# CH585SFR register map
Vendor: WCH Ltd.; Series: CH58x; File version: 1.1
CPU: RISC-V r0p0, little endian, no MPU, no FPU, 2 interrupt priority bits
Registers are 8-bit, read-write, reset 0x0 unless marked. A register's access mark holds for its fields unless they carry their own. Offsets are from the block's base; [hi:lo] are bit positions; lines under a group give offsets from that group; {n}, {i} and the like mark numbered series.

## SPI1
Base 0x40004400
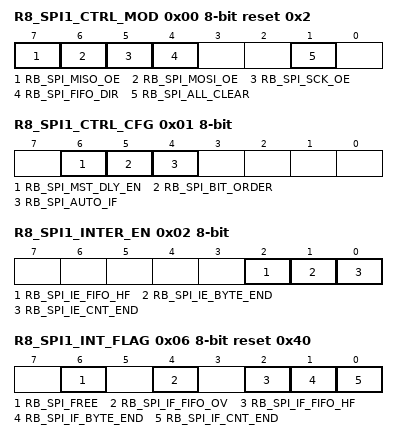
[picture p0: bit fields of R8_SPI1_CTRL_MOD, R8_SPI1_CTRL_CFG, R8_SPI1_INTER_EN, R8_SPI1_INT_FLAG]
0x00 R8_SPI1_CTRL_MOD reset 0x2 — RW, SPI1 mode control
  [7] RB_SPI_MISO_OE — RW, SPI MISO output enable
  [6] RB_SPI_MOSI_OE — RW, SPI MOSI output enable
  [5] RB_SPI_SCK_OE — RW, SPI SCK output enable
  [4] RB_SPI_FIFO_DIR — RW, SPI FIFO direction: 0=out(write @master mode), 1=in(read @master mode)
  [1] RB_SPI_ALL_CLEAR — RW, force clear SPI FIFO and count
0x01 R8_SPI1_CTRL_CFG — RW, SPI1 configuration control
  [6] RB_SPI_MST_DLY_EN — RW, SPI master input delay enable
  [5] RB_SPI_BIT_ORDER — RW, SPI bit data order: 0=MSB first, 1=LSB first
  [4] RB_SPI_AUTO_IF — RW, enable buffer/FIFO accessing to auto clear RB_SPI_IF_BYTE_END interrupt flag
0x02 R8_SPI1_INTER_EN — RW, SPI0 interrupt enable
  [2] RB_SPI_IE_FIFO_HF — RW, enable interrupt for SPI FIFO half
  [1] RB_SPI_IE_BYTE_END — RW, enable interrupt for SPI byte exchanged
  [0] RB_SPI_IE_CNT_END — RW, enable interrupt for SPI total byte count end
0x03 R8_SPI1_CLOCK_DIV reset 0x10 — RW, SPI1 master clock divisor;RW, SPI1 slave preset value
0x04 R8_SPI1_BUFFER reset not defined — RW, SPI1 data buffer
0x05 R8_SPI1_RUN_FLAG ro — RO, SPI1 work flag
  [5] RB_SPI_FIFO_READY — RO, SPI FIFO ready status
0x06 R8_SPI1_INT_FLAG reset 0x40 — RW1, SPI1 interrupt flag
  [6] RB_SPI_FREE — RO, current SPI free status
  [4] RB_SPI_IF_FIFO_OV — RW1, interrupt flag for SPI1 FIFO overflow
  [2] RB_SPI_IF_FIFO_HF — RW1, interrupt flag for SPI FIFO half
  [1] RB_SPI_IF_BYTE_END — RW1, interrupt flag for SPI byte exchanged
  [0] RB_SPI_IF_CNT_END — RW1, interrupt flag for SPI total byte count end
0x07 R8_SPI1_FIFO_COUNT — RW, SPI1 FIFO count status
  [3:0] R8_SPI1_FIFO_COUNT
0x0C R16_SPI1_TOTAL_CNT 16-bit — RW, SPI1 total byte count, only low 12 bit
  [11:0] R16_SPI1_TOTAL_CNT
0x10 R8_SPI1_FIFO reset not defined — RO/WO, SPI1 FIFO register
0x13 R8_SPI1_FIFO_COUNT1 ro — RO, SPI1 FIFO count status

## PWMx
Base 0x40005000
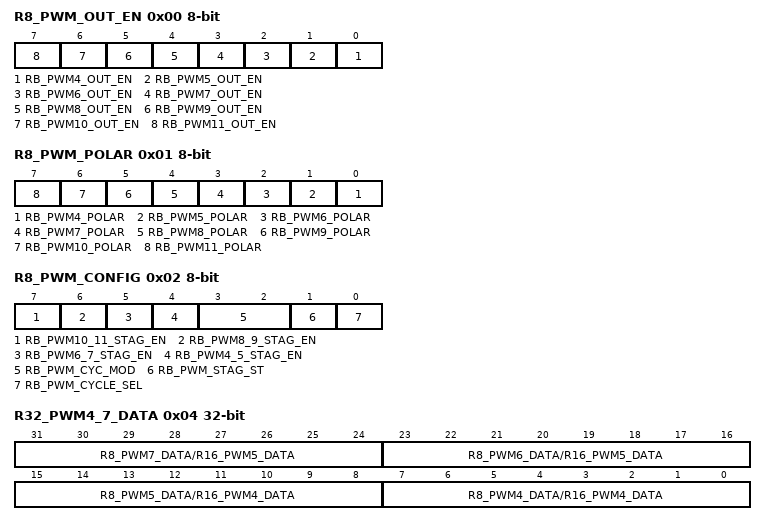
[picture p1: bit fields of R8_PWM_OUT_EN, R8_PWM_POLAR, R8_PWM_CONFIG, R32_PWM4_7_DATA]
0x00 R8_PWM_OUT_EN — RW, PWM output enable control
  [n-4] RB_PWM{n}_OUT_EN (n=4..11) — RW, PWM{n} output enable
0x01 R8_PWM_POLAR — RW, PWM output polarity control
  [n-4] RB_PWM{n}_POLAR (n=4..11) — RW, PWM{n} output polarity: 0=default low and high action, 1=default high and low action
0x02 R8_PWM_CONFIG reset not defined — RW, PWM configuration
  [7] RB_PWM10_11_STAG_EN — RW, PWM10/11 stagger output enable: 0=independent output, 1=stagger output
  [6] RB_PWM8_9_STAG_EN — RW, PWM8/9 stagger output enable: 0=independent output, 1=stagger output
  [5] RB_PWM6_7_STAG_EN — RW, PWM6/7 stagger output enable: 0=independent output, 1=stagger output
  [4] RB_PWM4_5_STAG_EN — RW, PWM4/5 stagger output enable: 0=independent output, 1=stagger output
  [3:2] RB_PWM_CYC_MOD — RW, PWM data width mode: 00=8 bits data, 01=7 bits data, 10=6 bits data, 11=5 bits data
  [1] RB_PWM_STAG_ST ro — RO, PWM stagger cycle status
  [0] RB_PWM_CYCLE_SEL — RW, PWM cycle selection: 0=256;128;64;32 clocks, 1=255;127;63;31 clocks
0x03 R8_PWM_CLOCK_DIV — RW, PWM clock divisor
0x04 R32_PWM4_7_DATA 32-bit reset not defined — RW, PWM data retention register group 1
  [31:24] R8_PWM7_DATA/R16_PWM5_DATA — RW, PWM7 data holding or PWM5 data holding(16bits wide)
  [23:16] R8_PWM6_DATA/R16_PWM5_DATA — RW, PWM6 data holding or PWM5 data holding(16bits wide)
  [15:8] R8_PWM5_DATA/R16_PWM4_DATA — RW, PWM5 data holding or PWM4 data holding(16bits wide)
  [7:0] R8_PWM4_DATA/R16_PWM4_DATA — RW, PWM4 data holding or PWM4 data holding(16bits wide)
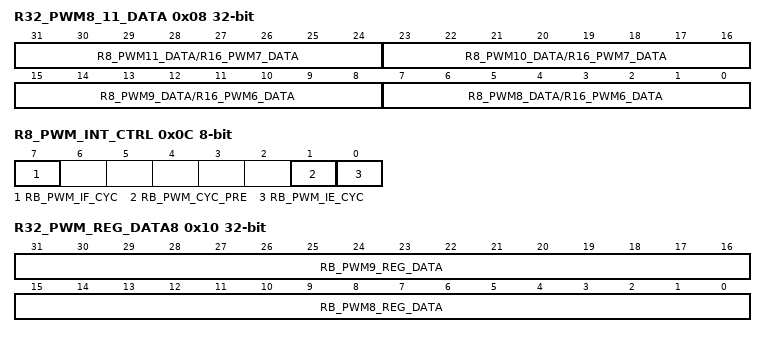
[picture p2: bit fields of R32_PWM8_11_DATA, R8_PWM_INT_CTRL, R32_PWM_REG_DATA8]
0x08 R32_PWM8_11_DATA 32-bit reset not defined — RW, PWM data retention register group 2
  [31:24] R8_PWM11_DATA/R16_PWM7_DATA — RW, PWM11 data holding or PWM7 data holding(16bits wide)
  [23:16] R8_PWM10_DATA/R16_PWM7_DATA — RW, PWM10 data holding or PWM7 data holding(16bits wide)
  [15:8] R8_PWM9_DATA/R16_PWM6_DATA — RW, PWM9 data holding or PWM6 data holding(16bits wide)
  [7:0] R8_PWM8_DATA/R16_PWM6_DATA — RW, PWM8 data holding or PWM6 data holding(16bits wide)
0x0C R8_PWM_INT_CTRL — RW, PWM interrupt control
  [7] RB_PWM_IF_CYC — RW1, interrupt flag for PWM cycle end
  [1] RB_PWM_CYC_PRE — RW, select PWM cycle interrupt point
  [0] RB_PWM_IE_CYC — RW, enable interrupt for PWM cycle end
0x10 R32_PWM_REG_DATA8 32-bit reset not defined — RW, PWM8/9 data register
  [31:16] RB_PWM9_REG_DATA — RW, 16 bit data of PWM9 channel
  [15:0] RB_PWM8_REG_DATA — RW, 16 bit data of PWM8 channel
0x14 R32_PWM_REG_CYCLE 32-bit reset not defined — RW, PWM cycle end register
  [15:0] RB_PWM_CYC_VALUE — RW, PWM End Cycles
